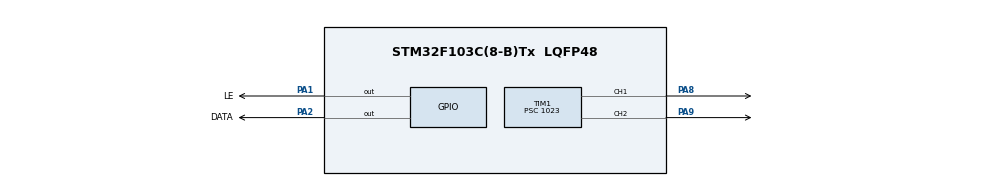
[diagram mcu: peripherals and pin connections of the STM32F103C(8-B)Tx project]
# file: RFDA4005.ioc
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Mcu.Family=STM32F1
Mcu.Name=STM32F103C(8-B)Tx
Mcu.Package=LQFP48
NVIC.PriorityGroup=NVIC_PRIORITYGROUP_4
NVIC.TIM1_BRK_IRQn=true\:0\:0\:false\:false\:true\:true\:true\:true
NVIC.TIM1_UP_IRQn=true\:0\:0\:false\:false\:true\:true\:true\:true
PA1.GPIO_Label=LE
PA1.GPIO_Speed=GPIO_SPEED_FREQ_HIGH
PA1.Signal=GPIO_Output
PA13.Mode=Serial_Wire
PA13.Signal=SYS_JTMS-SWDIO
PA14.Mode=Serial_Wire
PA14.Signal=SYS_JTCK-SWCLK
PA2.GPIO_Label=DATA
PA2.GPIO_Speed=GPIO_SPEED_FREQ_HIGH
PA2.Signal=GPIO_Output
PA8.GPIO_Speed=GPIO_SPEED_FREQ_HIGH
PA8.Signal=S_TIM1_CH1
PA9.GPIO_Speed=GPIO_SPEED_FREQ_HIGH
PA9.Signal=S_TIM1_CH2
PD0-OSC_IN.Mode=HSE-External-Oscillator
PD0-OSC_IN.Signal=RCC_OSC_IN
PD1-OSC_OUT.Mode=HSE-External-Oscillator
PD1-OSC_OUT.Signal=RCC_OSC_OUT
ProjectManager.HeapSize=0x200
ProjectManager.StackSize=0x400
ProjectManager.TargetToolchain=STM32CubeIDE
RCC.APB1Freq_Value=8000000
RCC.APB2Freq_Value=8000000
SH.S_TIM1_CH1.0=TIM1_CH1,Output Compare1 CH1
SH.S_TIM1_CH2.0=TIM1_CH2,Output Compare2 CH2
TIM1.Channel-Output\ Compare1\ CH1=TIM_CHANNEL_1
TIM1.Channel-Output\ Compare2\ CH2=TIM_CHANNEL_2
TIM1.CounterMode=TIM_COUNTERMODE_CENTERALIGNED3
TIM1.OCMode_1=TIM_OCMODE_TOGGLE
TIM1.OCMode_2=TIM_OCMODE_TOGGLE
TIM1.Period=1023
TIM1.Prescaler=1023
TIM1.Pulse-Output\ Compare1\ CH1=500
TIM1.Pulse-Output\ Compare2\ CH2=500
TIM1.RepetitionCounter=1
TIM1.TIM_MasterOutputTrigger=TIM_TRGO_RESET
VP_TIM1_VS_ClockSourceINT.Mode=Internal
board=custom

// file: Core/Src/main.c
/* USER CODE BEGIN Header */
/**
  ******************************************************************************
  * @file           : main.c
  * @brief          : Main program body
  ******************************************************************************
  * @attention
  *
  * Copyright (c) 2023 STMicroelectronics.
  * All rights reserved.
  *
  * This software is licensed under terms that can be found in the LICENSE file
  * in the root directory of this software component.
  * If no LICENSE file comes with this software, it is provided AS-IS.
  *
  ******************************************************************************
  */
/* USER CODE END Header */
#include "main.h"
#include "tim.h"
#include "gpio.h"

/* USER CODE BEGIN Includes */
#include "RFDA_protocol.h"
/* USER CODE END Includes */

/* USER CODE BEGIN PV */
uint8_t idata = 0;  //example counter in main
uint8_t k = 0;
uint8_t t = 0;
/* USER CODE END PV */

void SystemClock_Config(void);

int main(void)
{

  /* MCU Configuration--------------------------------------------------------*/

  /* Reset of all peripherals, Initializes the Flash interface and the Systick. */
  LL_APB2_GRP1_EnableClock(LL_APB2_GRP1_PERIPH_AFIO);
  LL_APB1_GRP1_EnableClock(LL_APB1_GRP1_PERIPH_PWR);

  /* System interrupt init*/
  NVIC_SetPriorityGrouping(NVIC_PRIORITYGROUP_4);

  /* SysTick_IRQn interrupt configuration */
  NVIC_SetPriority(SysTick_IRQn, NVIC_EncodePriority(NVIC_GetPriorityGrouping(),15, 0));

  /** NOJTAG: JTAG-DP Disabled and SW-DP Enabled
  */
  LL_GPIO_AF_Remap_SWJ_NOJTAG();

  /* Configure the system clock */
  SystemClock_Config();

  /* Initialize all configured peripherals */
  MX_GPIO_Init();
  MX_TIM1_Init();
  /* USER CODE BEGIN 2 */
  //Timer settings
  TIM1->CR2|=TIM_CR1_URS; //Only counter overflow/underflow generates an update interrupt or DMA request
  TIM1->DIER|=TIM_DIER_BIE;//Break iterrupt enable
  TIM1->DIER|=TIM_DIER_UIE;//Update interrupt enable

  /* USER CODE END 2 */

  /* Infinite loop */
  while (1)
  {
	  for(k=0U;k<=5U;k++){
	  RFDA(~(1<<k));
	  LL_mDelay(500);
	  }
  }
}

void SystemClock_Config(void)
{
  LL_FLASH_SetLatency(LL_FLASH_LATENCY_0);
  while(LL_FLASH_GetLatency()!= LL_FLASH_LATENCY_0)
  {
  }
  LL_RCC_HSI_SetCalibTrimming(16);
  LL_RCC_HSI_Enable();

   /* Wait till HSI is ready */
  while(LL_RCC_HSI_IsReady() != 1)
  {

  }
  LL_RCC_SetAHBPrescaler(LL_RCC_SYSCLK_DIV_1);
  LL_RCC_SetAPB1Prescaler(LL_RCC_APB1_DIV_1);
  LL_RCC_SetAPB2Prescaler(LL_RCC_APB2_DIV_1);
  LL_RCC_SetSysClkSource(LL_RCC_SYS_CLKSOURCE_HSI);

   /* Wait till System clock is ready */
  while(LL_RCC_GetSysClkSource() != LL_RCC_SYS_CLKSOURCE_STATUS_HSI)
  {

  }
  LL_Init1msTick(8000000);
  LL_SetSystemCoreClock(8000000);
}

void Error_Handler(void)
{
  __disable_irq();
  while (1)
  {
  }
}
